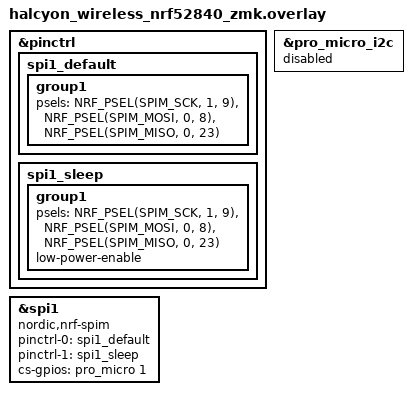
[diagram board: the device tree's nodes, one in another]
/*
 * Copyright (c) 2026 Splitkb.com
 *
 * SPDX-License-Identifier: MIT
 */
 
&pinctrl {
    spi1_default: spi1_default {
        group1 {
            psels = <NRF_PSEL(SPIM_SCK, 1, 9)>,
                <NRF_PSEL(SPIM_MOSI, 0, 8)>,
                <NRF_PSEL(SPIM_MISO, 0, 23)>; // NC
        };
    };
    spi1_sleep: spi1_sleep {
        group1 {
            psels = <NRF_PSEL(SPIM_SCK, 1, 9)>,
                <NRF_PSEL(SPIM_MOSI, 0, 8)>,
                <NRF_PSEL(SPIM_MISO, 0, 23)>; // NC
            low-power-enable;
        };
    };
};

nice_view_spi: &spi1 {
    compatible = "nordic,nrf-spim";
    pinctrl-0 = <&spi1_default>;
    pinctrl-1 = <&spi1_sleep>;
    pinctrl-names = "default", "sleep";
    cs-gpios = <&pro_micro 1 GPIO_ACTIVE_HIGH>;
};

&pro_micro_i2c {
    status = "disabled";
};
